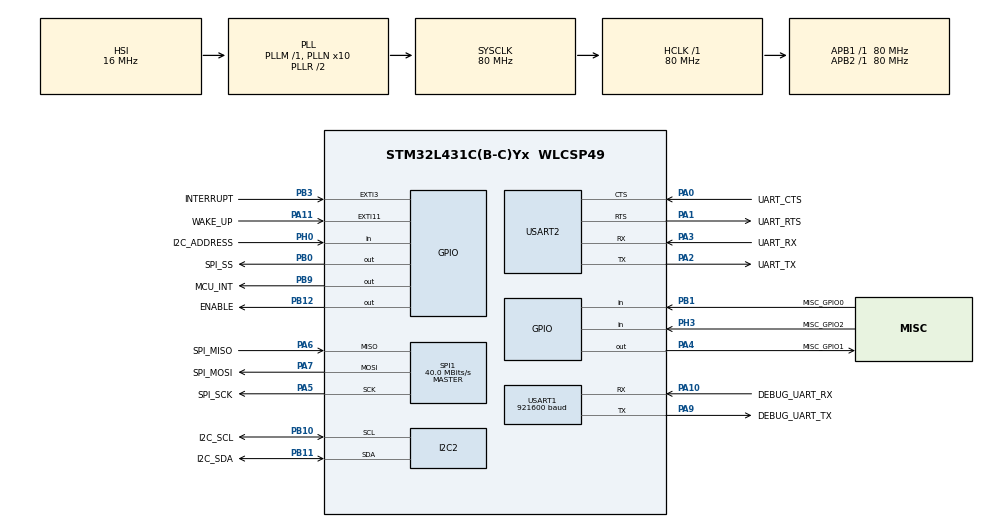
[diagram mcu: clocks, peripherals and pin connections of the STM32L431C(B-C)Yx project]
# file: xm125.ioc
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Dma.Request0=USART2_RX
Dma.Request1=USART2_TX
Dma.Request2=SPI1_RX
Dma.Request3=SPI1_TX
Dma.Request4=USART1_RX
Dma.SPI1_RX.2.Direction=DMA_PERIPH_TO_MEMORY
Dma.SPI1_RX.2.Instance=DMA1_Channel2
Dma.SPI1_RX.2.MemDataAlignment=DMA_MDATAALIGN_HALFWORD
Dma.SPI1_RX.2.MemInc=DMA_MINC_ENABLE
Dma.SPI1_RX.2.Mode=DMA_NORMAL
Dma.SPI1_RX.2.PeriphDataAlignment=DMA_PDATAALIGN_HALFWORD
Dma.SPI1_RX.2.PeriphInc=DMA_PINC_DISABLE
Dma.SPI1_RX.2.Priority=DMA_PRIORITY_LOW
Dma.SPI1_TX.3.Direction=DMA_MEMORY_TO_PERIPH
Dma.SPI1_TX.3.Instance=DMA1_Channel3
Dma.SPI1_TX.3.MemDataAlignment=DMA_MDATAALIGN_HALFWORD
Dma.SPI1_TX.3.MemInc=DMA_MINC_ENABLE
Dma.SPI1_TX.3.Mode=DMA_NORMAL
Dma.SPI1_TX.3.PeriphDataAlignment=DMA_PDATAALIGN_HALFWORD
Dma.SPI1_TX.3.PeriphInc=DMA_PINC_DISABLE
Dma.SPI1_TX.3.Priority=DMA_PRIORITY_LOW
Dma.USART1_RX.4.Direction=DMA_PERIPH_TO_MEMORY
Dma.USART1_RX.4.Instance=DMA1_Channel5
Dma.USART1_RX.4.MemDataAlignment=DMA_MDATAALIGN_BYTE
Dma.USART1_RX.4.MemInc=DMA_MINC_ENABLE
Dma.USART1_RX.4.Mode=DMA_NORMAL
Dma.USART1_RX.4.PeriphDataAlignment=DMA_PDATAALIGN_BYTE
Dma.USART1_RX.4.PeriphInc=DMA_PINC_DISABLE
Dma.USART1_RX.4.Priority=DMA_PRIORITY_LOW
Dma.USART2_RX.0.Direction=DMA_PERIPH_TO_MEMORY
Dma.USART2_RX.0.Instance=DMA1_Channel6
Dma.USART2_RX.0.MemDataAlignment=DMA_MDATAALIGN_BYTE
Dma.USART2_RX.0.MemInc=DMA_MINC_ENABLE
Dma.USART2_RX.0.Mode=DMA_NORMAL
Dma.USART2_RX.0.PeriphDataAlignment=DMA_PDATAALIGN_BYTE
Dma.USART2_RX.0.PeriphInc=DMA_PINC_DISABLE
Dma.USART2_RX.0.Priority=DMA_PRIORITY_LOW
Dma.USART2_TX.1.Direction=DMA_MEMORY_TO_PERIPH
Dma.USART2_TX.1.Instance=DMA1_Channel7
Dma.USART2_TX.1.MemDataAlignment=DMA_MDATAALIGN_BYTE
Dma.USART2_TX.1.MemInc=DMA_MINC_ENABLE
Dma.USART2_TX.1.Mode=DMA_NORMAL
Dma.USART2_TX.1.PeriphDataAlignment=DMA_PDATAALIGN_BYTE
Dma.USART2_TX.1.PeriphInc=DMA_PINC_DISABLE
Dma.USART2_TX.1.Priority=DMA_PRIORITY_LOW
I2C2.OwnAddress=0x52
I2C2.Timing=0x10D19CE4
Mcu.Family=STM32L4
Mcu.Name=STM32L431C(B-C)Yx
Mcu.Package=WLCSP49
NVIC.DMA1_Channel2_IRQn=true\:0\:0\:false\:false\:true\:false\:true\:true
NVIC.DMA1_Channel3_IRQn=true\:0\:0\:false\:false\:true\:false\:true\:true
NVIC.DMA1_Channel5_IRQn=true\:0\:0\:false\:false\:true\:false\:true\:true
NVIC.DMA1_Channel6_IRQn=true\:0\:0\:false\:false\:true\:false\:true\:true
NVIC.DMA1_Channel7_IRQn=true\:0\:0\:false\:false\:true\:false\:true\:true
NVIC.EXTI15_10_IRQn=true\:0\:0\:false\:false\:true\:true\:true\:true
NVIC.EXTI3_IRQn=true\:0\:0\:false\:false\:true\:true\:true\:true
NVIC.I2C2_EV_IRQn=true\:0\:0\:false\:false\:true\:true\:true\:true
NVIC.PriorityGroup=NVIC_PRIORITYGROUP_4
NVIC.RTC_Alarm_IRQn=true\:0\:0\:false\:false\:true\:true\:true\:true
NVIC.RTC_WKUP_IRQn=true\:0\:0\:false\:false\:true\:true\:true\:true
NVIC.USART2_IRQn=true\:0\:0\:false\:false\:true\:true\:true\:true
PA0.GPIO_Label=UART_CTS
PA0.Mode=CTS_RTS
PA0.Signal=USART2_CTS
PA1.GPIO_Label=UART_RTS
PA1.Mode=CTS_RTS
PA1.Signal=USART2_RTS
PA10.GPIO_Label=DEBUG_UART_RX
PA10.Mode=Asynchronous
PA10.Signal=USART1_RX
PA11.GPIO_Label=WAKE_UP
PA11.GPIO_ModeDefaultEXTI=GPIO_MODE_IT_RISING_FALLING
PA11.GPIO_PuPd=GPIO_PULLDOWN
PA11.Signal=GPXTI11
PA2.GPIO_Label=UART_TX
PA2.Mode=Asynchronous
PA2.Signal=USART2_TX
PA3.GPIO_Label=UART_RX
PA3.Mode=Asynchronous
PA3.Signal=USART2_RX
PA4.GPIO_Label=MISC_GPIO1
PA4.GPIO_PuPd=GPIO_PULLDOWN
PA4.GPIO_Speed=GPIO_SPEED_FREQ_VERY_HIGH
PA4.Signal=GPIO_Output
PA5.GPIO_Label=SPI_SCK
PA5.Mode=Full_Duplex_Master
PA5.Signal=SPI1_SCK
PA6.GPIO_Label=SPI_MISO
PA6.Mode=Full_Duplex_Master
PA6.Signal=SPI1_MISO
PA7.GPIO_Label=SPI_MOSI
PA7.Mode=Full_Duplex_Master
PA7.Signal=SPI1_MOSI
PA9.GPIO_Label=DEBUG_UART_TX
PA9.Mode=Asynchronous
PA9.Signal=USART1_TX
PB0.GPIO_Label=SPI_SS
PB0.GPIO_ModeDefaultOutputPP=GPIO_MODE_OUTPUT_PP
PB0.GPIO_Speed=GPIO_SPEED_FREQ_VERY_HIGH
PB0.Signal=GPIO_Output
PB1.GPIO_Label=MISC_GPIO0
PB1.GPIO_PuPd=GPIO_PULLDOWN
PB1.Signal=GPIO_Input
PB10.GPIO_Label=I2C_SCL
PB10.GPIO_Pu=GPIO_PULLUP
PB10.Mode=I2C
PB10.Signal=I2C2_SCL
PB11.GPIO_Label=I2C_SDA
PB11.GPIO_Pu=GPIO_PULLUP
PB11.Mode=I2C
PB11.Signal=I2C2_SDA
PB12.GPIO_Label=ENABLE
PB12.GPIO_Speed=GPIO_SPEED_FREQ_VERY_HIGH
PB12.PinState=GPIO_PIN_RESET
PB12.Signal=GPIO_Output
PB3\ (JTDO-TRACESWO).GPIO_Label=INTERRUPT
PB3\ (JTDO-TRACESWO).GPIO_PuPd=GPIO_PULLDOWN
PB3\ (JTDO-TRACESWO).Signal=GPXTI3
PB9.GPIO_Label=MCU_INT
PB9.GPIO_Speed=GPIO_SPEED_FREQ_VERY_HIGH
PB9.Signal=GPIO_Output
PH0-OSC_IN\ (PH0).GPIO_Label=I2C_ADDRESS
PH0-OSC_IN\ (PH0).GPIO_PuPd=GPIO_PULLDOWN
PH0-OSC_IN\ (PH0).Signal=GPIO_Input
PH3-BOOT0.GPIO_Label=MISC_GPIO2
PH3-BOOT0.GPIO_PuPd=GPIO_PULLDOWN
PH3-BOOT0.Signal=GPIO_Input
ProjectManager.HeapSize=0x200
ProjectManager.StackSize=0x1400
ProjectManager.TargetToolchain=STM32CubeIDE
RCC.ADCFreq_Value=64000000
RCC.AHBFreq_Value=80000000
RCC.APB1Freq_Value=80000000
RCC.APB1TimFreq_Value=80000000
RCC.APB2Freq_Value=80000000
RCC.APB2TimFreq_Value=80000000
RCC.CortexFreq_Value=80000000
RCC.HCLKFreq_Value=80000000
RCC.HSE_VALUE=8000000
RCC.HSI48_VALUE=48000000
RCC.HSI_VALUE=16000000
RCC.LSE_VALUE=32768
RCC.MSI_VALUE=4000000
RCC.PLLN=10
RCC.PLLSourceVirtual=RCC_PLLSOURCE_HSI
RCC.SYSCLKFreq_VALUE=80000000
RCC.SYSCLKSource=RCC_SYSCLKSOURCE_PLLCLK
RCC.VCOOutputFreq_Value=160000000
RTC.Alarm-Alarm\ A=RTC_ALARM_A
RTC.AsynchPrediv=31
RTC.Format=RTC_FORMAT_BIN
RTC.SynchPrediv=999
SPI1.BaudRatePrescaler=SPI_BAUDRATEPRESCALER_2
SPI1.CalculateBaudRate=40.0 MBits/s
SPI1.DataSize=SPI_DATASIZE_16BIT
SPI1.Direction=SPI_DIRECTION_2LINES
SPI1.Mode=SPI_MODE_MASTER
SPI1.VirtualType=VM_MASTER
USART1.BaudRate=921600
USART1.Parity=PARITY_EVEN
USART1.VirtualMode-Asynchronous=VM_ASYNC
USART1.WordLength=WORDLENGTH_9B
USART2.VirtualMode-Asynchronous=VM_ASYNC
VP_RTC_VS_RTC_Activate.Mode=RTC_Enabled
VP_RTC_VS_RTC_Alarm_A_Intern.Mode=Alarm A
VP_RTC_VS_RTC_Calendar.Mode=RTC_Calendar
VP_RTC_VS_RTC_WakeUp_intern.Mode=WakeUp
board=custom

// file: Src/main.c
/* USER CODE BEGIN Header */
/**
 ******************************************************************************
 * @file           : main.c
 * @brief          : Main program body
 ******************************************************************************
 * @attention
 *
 * <h2><center>&copy; Copyright (c) 2022 STMicroelectronics.
 * All rights reserved.</center></h2>
 *
 * This software component is licensed by ST under BSD 3-Clause license,
 * the "License"; You may not use this file except in compliance with the
 * License. You may obtain a copy of the License at:
 *                        opensource.org/licenses/BSD-3-Clause
 *
 ******************************************************************************
 */
/* USER CODE END Header */
#include "main.h"

/* USER CODE BEGIN Includes */

#include <inttypes.h>
#include <stdbool.h>
#include <stdio.h>

#include "acc_integration.h"

/* USER CODE END Includes */

/* USER CODE BEGIN PD */

extern int acconeer_main(int argc, char *argv[]);

/* USER CODE END PD */

I2C_HandleTypeDef hi2c2;

RTC_HandleTypeDef hrtc;

SPI_HandleTypeDef hspi1;
DMA_HandleTypeDef hdma_spi1_rx;
DMA_HandleTypeDef hdma_spi1_tx;

UART_HandleTypeDef huart1;
UART_HandleTypeDef huart2;
DMA_HandleTypeDef hdma_usart1_rx;
DMA_HandleTypeDef hdma_usart2_rx;
DMA_HandleTypeDef hdma_usart2_tx;

void SystemClock_Config(void);
static void MX_GPIO_Init(void);
static void MX_DMA_Init(void);
static void MX_USART2_UART_Init(void);
static void MX_SPI1_Init(void);
static void MX_I2C2_Init(void);
static void MX_USART1_UART_Init(void);
static void MX_RTC_Init(void);

int main(void)
{

  /* MCU Configuration--------------------------------------------------------*/

  /* Reset of all peripherals, Initializes the Flash interface and the Systick. */
  HAL_Init();

  /* Configure the system clock */
  SystemClock_Config();

  /* Initialize all configured peripherals */
  MX_GPIO_Init();
  MX_DMA_Init();
  MX_USART2_UART_Init();
  MX_SPI1_Init();
  MX_I2C2_Init();
  MX_USART1_UART_Init();
  MX_RTC_Init();
  /* USER CODE BEGIN 2 */

//  acconeer_main(0, NULL);
  acconeer_main_JJH_V2(0, NULL);

  /* USER CODE END 2 */

  /* Infinite loop */
	while (1)
	{

	}
}

void SystemClock_Config(void)
{
  RCC_OscInitTypeDef RCC_OscInitStruct = {0};
  RCC_ClkInitTypeDef RCC_ClkInitStruct = {0};

  /** Configure the main internal regulator output voltage
  */
  if (HAL_PWREx_ControlVoltageScaling(PWR_REGULATOR_VOLTAGE_SCALE1) != HAL_OK)
  {
    Error_Handler();
  }

  /** Initializes the RCC Oscillators according to the specified parameters
  * in the RCC_OscInitTypeDef structure.
  */
  RCC_OscInitStruct.OscillatorType = RCC_OSCILLATORTYPE_HSI|RCC_OSCILLATORTYPE_LSI;
  RCC_OscInitStruct.HSIState = RCC_HSI_ON;
  RCC_OscInitStruct.HSICalibrationValue = RCC_HSICALIBRATION_DEFAULT;
  RCC_OscInitStruct.LSIState = RCC_LSI_ON;
  RCC_OscInitStruct.PLL.PLLState = RCC_PLL_ON;
  RCC_OscInitStruct.PLL.PLLSource = RCC_PLLSOURCE_HSI;
  RCC_OscInitStruct.PLL.PLLM = 1;
  RCC_OscInitStruct.PLL.PLLN = 10;
  RCC_OscInitStruct.PLL.PLLP = RCC_PLLP_DIV7;
  RCC_OscInitStruct.PLL.PLLQ = RCC_PLLQ_DIV2;
  RCC_OscInitStruct.PLL.PLLR = RCC_PLLR_DIV2;
  if (HAL_RCC_OscConfig(&RCC_OscInitStruct) != HAL_OK)
  {
    Error_Handler();
  }

  /** Initializes the CPU, AHB and APB buses clocks
  */
  RCC_ClkInitStruct.ClockType = RCC_CLOCKTYPE_HCLK|RCC_CLOCKTYPE_SYSCLK
                              |RCC_CLOCKTYPE_PCLK1|RCC_CLOCKTYPE_PCLK2;
  RCC_ClkInitStruct.SYSCLKSource = RCC_SYSCLKSOURCE_PLLCLK;
  RCC_ClkInitStruct.AHBCLKDivider = RCC_SYSCLK_DIV1;
  RCC_ClkInitStruct.APB1CLKDivider = RCC_HCLK_DIV1;
  RCC_ClkInitStruct.APB2CLKDivider = RCC_HCLK_DIV1;

  if (HAL_RCC_ClockConfig(&RCC_ClkInitStruct, FLASH_LATENCY_4) != HAL_OK)
  {
    Error_Handler();
  }
}

static void MX_I2C2_Init(void)
{

  hi2c2.Instance = I2C2;
  hi2c2.Init.Timing = 0x10D19CE4;
  hi2c2.Init.OwnAddress1 = 164;
  hi2c2.Init.AddressingMode = I2C_ADDRESSINGMODE_7BIT;
  hi2c2.Init.DualAddressMode = I2C_DUALADDRESS_DISABLE;
  hi2c2.Init.OwnAddress2 = 0;
  hi2c2.Init.OwnAddress2Masks = I2C_OA2_NOMASK;
  hi2c2.Init.GeneralCallMode = I2C_GENERALCALL_DISABLE;
  hi2c2.Init.NoStretchMode = I2C_NOSTRETCH_DISABLE;
  if (HAL_I2C_Init(&hi2c2) != HAL_OK)
  {
    Error_Handler();
  }

  /** Configure Analogue filter
  */
  if (HAL_I2CEx_ConfigAnalogFilter(&hi2c2, I2C_ANALOGFILTER_ENABLE) != HAL_OK)
  {
    Error_Handler();
  }

  /** Configure Digital filter
  */
  if (HAL_I2CEx_ConfigDigitalFilter(&hi2c2, 0) != HAL_OK)
  {
    Error_Handler();
  }

}

static void MX_RTC_Init(void)
{

  RTC_TimeTypeDef sTime = {0};
  RTC_DateTypeDef sDate = {0};
  RTC_AlarmTypeDef sAlarm = {0};

  /** Initialize RTC Only
  */
  hrtc.Instance = RTC;
  hrtc.Init.HourFormat = RTC_HOURFORMAT_24;
  hrtc.Init.AsynchPrediv = 31;
  hrtc.Init.SynchPrediv = 999;
  hrtc.Init.OutPut = RTC_OUTPUT_DISABLE;
  hrtc.Init.OutPutRemap = RTC_OUTPUT_REMAP_NONE;
  hrtc.Init.OutPutPolarity = RTC_OUTPUT_POLARITY_HIGH;
  hrtc.Init.OutPutType = RTC_OUTPUT_TYPE_OPENDRAIN;
  if (HAL_RTC_Init(&hrtc) != HAL_OK)
  {
    Error_Handler();
  }

  /** Initialize RTC and set the Time and Date
  */
  sTime.Hours = 0;
  sTime.Minutes = 0;
  sTime.Seconds = 0;
  sTime.DayLightSaving = RTC_DAYLIGHTSAVING_NONE;
  sTime.StoreOperation = RTC_STOREOPERATION_RESET;
  if (HAL_RTC_SetTime(&hrtc, &sTime, RTC_FORMAT_BIN) != HAL_OK)
  {
    Error_Handler();
  }
  sDate.WeekDay = RTC_WEEKDAY_MONDAY;
  sDate.Month = RTC_MONTH_JANUARY;
  sDate.Date = 1;
  sDate.Year = 0;

  if (HAL_RTC_SetDate(&hrtc, &sDate, RTC_FORMAT_BIN) != HAL_OK)
  {
    Error_Handler();
  }

  /** Enable the Alarm A
  */
  sAlarm.AlarmTime.Hours = 0;
  sAlarm.AlarmTime.Minutes = 0;
  sAlarm.AlarmTime.Seconds = 0;
  sAlarm.AlarmTime.SubSeconds = 0;
  sAlarm.AlarmTime.DayLightSaving = RTC_DAYLIGHTSAVING_NONE;
  sAlarm.AlarmTime.StoreOperation = RTC_STOREOPERATION_RESET;
  sAlarm.AlarmMask = RTC_ALARMMASK_NONE;
  sAlarm.AlarmSubSecondMask = RTC_ALARMSUBSECONDMASK_ALL;
  sAlarm.AlarmDateWeekDaySel = RTC_ALARMDATEWEEKDAYSEL_DATE;
  sAlarm.AlarmDateWeekDay = 1;
  sAlarm.Alarm = RTC_ALARM_A;
  if (HAL_RTC_SetAlarm_IT(&hrtc, &sAlarm, RTC_FORMAT_BIN) != HAL_OK)
  {
    Error_Handler();
  }

}

static void MX_SPI1_Init(void)
{

  /* SPI1 parameter configuration*/
  hspi1.Instance = SPI1;
  hspi1.Init.Mode = SPI_MODE_MASTER;
  hspi1.Init.Direction = SPI_DIRECTION_2LINES;
  hspi1.Init.DataSize = SPI_DATASIZE_16BIT;
  hspi1.Init.CLKPolarity = SPI_POLARITY_LOW;
  hspi1.Init.CLKPhase = SPI_PHASE_1EDGE;
  hspi1.Init.NSS = SPI_NSS_SOFT;
  hspi1.Init.BaudRatePrescaler = SPI_BAUDRATEPRESCALER_2;
  hspi1.Init.FirstBit = SPI_FIRSTBIT_MSB;
  hspi1.Init.TIMode = SPI_TIMODE_DISABLE;
  hspi1.Init.CRCCalculation = SPI_CRCCALCULATION_DISABLE;
  hspi1.Init.CRCPolynomial = 7;
  hspi1.Init.CRCLength = SPI_CRC_LENGTH_DATASIZE;
  hspi1.Init.NSSPMode = SPI_NSS_PULSE_ENABLE;
  if (HAL_SPI_Init(&hspi1) != HAL_OK)
  {
    Error_Handler();
  }

}

static void MX_USART1_UART_Init(void)
{

  huart1.Instance = USART1;
  huart1.Init.BaudRate = 921600;
  huart1.Init.WordLength = UART_WORDLENGTH_9B;
  huart1.Init.StopBits = UART_STOPBITS_1;
  huart1.Init.Parity = UART_PARITY_EVEN;
  huart1.Init.Mode = UART_MODE_TX_RX;
  huart1.Init.HwFlowCtl = UART_HWCONTROL_NONE;
  huart1.Init.OverSampling = UART_OVERSAMPLING_16;
  huart1.Init.OneBitSampling = UART_ONE_BIT_SAMPLE_DISABLE;
  huart1.AdvancedInit.AdvFeatureInit = UART_ADVFEATURE_NO_INIT;
  if (HAL_UART_Init(&huart1) != HAL_OK)
  {
    Error_Handler();
  }

}

static void MX_USART2_UART_Init(void)
{

  huart2.Instance = USART2;
  huart2.Init.BaudRate = 115200;
  huart2.Init.WordLength = UART_WORDLENGTH_8B;
  huart2.Init.StopBits = UART_STOPBITS_1;
  huart2.Init.Parity = UART_PARITY_NONE;
  huart2.Init.Mode = UART_MODE_TX_RX;
  huart2.Init.HwFlowCtl = UART_HWCONTROL_RTS_CTS;
  huart2.Init.OverSampling = UART_OVERSAMPLING_16;
  huart2.Init.OneBitSampling = UART_ONE_BIT_SAMPLE_DISABLE;
  huart2.AdvancedInit.AdvFeatureInit = UART_ADVFEATURE_NO_INIT;
  if (HAL_UART_Init(&huart2) != HAL_OK)
  {
    Error_Handler();
  }

}

static void MX_DMA_Init(void)
{

  /* DMA controller clock enable */
  __HAL_RCC_DMA1_CLK_ENABLE();

  /* DMA interrupt init */
  /* DMA1_Channel2_IRQn interrupt configuration */
  HAL_NVIC_SetPriority(DMA1_Channel2_IRQn, 0, 0);
  HAL_NVIC_EnableIRQ(DMA1_Channel2_IRQn);
  /* DMA1_Channel3_IRQn interrupt configuration */
  HAL_NVIC_SetPriority(DMA1_Channel3_IRQn, 0, 0);
  HAL_NVIC_EnableIRQ(DMA1_Channel3_IRQn);
  /* DMA1_Channel5_IRQn interrupt configuration */
  HAL_NVIC_SetPriority(DMA1_Channel5_IRQn, 0, 0);
  HAL_NVIC_EnableIRQ(DMA1_Channel5_IRQn);
  /* DMA1_Channel6_IRQn interrupt configuration */
  HAL_NVIC_SetPriority(DMA1_Channel6_IRQn, 0, 0);
  HAL_NVIC_EnableIRQ(DMA1_Channel6_IRQn);
  /* DMA1_Channel7_IRQn interrupt configuration */
  HAL_NVIC_SetPriority(DMA1_Channel7_IRQn, 0, 0);
  HAL_NVIC_EnableIRQ(DMA1_Channel7_IRQn);

}

static void MX_GPIO_Init(void)
{
  GPIO_InitTypeDef GPIO_InitStruct = {0};

  /* GPIO Ports Clock Enable */
  __HAL_RCC_GPIOB_CLK_ENABLE();
  __HAL_RCC_GPIOH_CLK_ENABLE();
  __HAL_RCC_GPIOA_CLK_ENABLE();

  /*Configure GPIO pin Output Level */
  HAL_GPIO_WritePin(GPIOB, MCU_INT_Pin|ENABLE_Pin|SPI_SS_Pin, GPIO_PIN_RESET);

  /*Configure GPIO pin Output Level */
  HAL_GPIO_WritePin(MISC_GPIO1_GPIO_Port, MISC_GPIO1_Pin, GPIO_PIN_RESET);

  /*Configure GPIO pin : INTERRUPT_Pin */
  GPIO_InitStruct.Pin = INTERRUPT_Pin;
  GPIO_InitStruct.Mode = GPIO_MODE_IT_RISING;
  GPIO_InitStruct.Pull = GPIO_PULLDOWN;
  HAL_GPIO_Init(INTERRUPT_GPIO_Port, &GPIO_InitStruct);

  /*Configure GPIO pins : MISC_GPIO2_Pin I2C_ADDRESS_Pin */
  GPIO_InitStruct.Pin = MISC_GPIO2_Pin|I2C_ADDRESS_Pin;
  GPIO_InitStruct.Mode = GPIO_MODE_INPUT;
  GPIO_InitStruct.Pull = GPIO_PULLDOWN;
  HAL_GPIO_Init(GPIOH, &GPIO_InitStruct);

  /*Configure GPIO pin : WAKE_UP_Pin */
  GPIO_InitStruct.Pin = WAKE_UP_Pin;
  GPIO_InitStruct.Mode = GPIO_MODE_IT_RISING_FALLING;
  GPIO_InitStruct.Pull = GPIO_PULLDOWN;
  HAL_GPIO_Init(WAKE_UP_GPIO_Port, &GPIO_InitStruct);

  /*Configure GPIO pins : MCU_INT_Pin ENABLE_Pin SPI_SS_Pin */
  GPIO_InitStruct.Pin = MCU_INT_Pin|ENABLE_Pin|SPI_SS_Pin;
  GPIO_InitStruct.Mode = GPIO_MODE_OUTPUT_PP;
  GPIO_InitStruct.Pull = GPIO_NOPULL;
  GPIO_InitStruct.Speed = GPIO_SPEED_FREQ_VERY_HIGH;
  HAL_GPIO_Init(GPIOB, &GPIO_InitStruct);

  /*Configure GPIO pin : MISC_GPIO0_Pin */
  GPIO_InitStruct.Pin = MISC_GPIO0_Pin;
  GPIO_InitStruct.Mode = GPIO_MODE_INPUT;
  GPIO_InitStruct.Pull = GPIO_PULLDOWN;
  HAL_GPIO_Init(MISC_GPIO0_GPIO_Port, &GPIO_InitStruct);

  /*Configure GPIO pin : MISC_GPIO1_Pin */
  GPIO_InitStruct.Pin = MISC_GPIO1_Pin;
  GPIO_InitStruct.Mode = GPIO_MODE_OUTPUT_PP;
  GPIO_InitStruct.Pull = GPIO_PULLDOWN;
  GPIO_InitStruct.Speed = GPIO_SPEED_FREQ_VERY_HIGH;
  HAL_GPIO_Init(MISC_GPIO1_GPIO_Port, &GPIO_InitStruct);

  /* EXTI interrupt init*/
  HAL_NVIC_SetPriority(EXTI3_IRQn, 0, 0);
  HAL_NVIC_EnableIRQ(EXTI3_IRQn);

  HAL_NVIC_SetPriority(EXTI15_10_IRQn, 0, 0);
  HAL_NVIC_EnableIRQ(EXTI15_10_IRQn);

}

void Error_Handler(void)
{
  /* USER CODE BEGIN Error_Handler_Debug */
	/* User can add his own implementation to report the HAL error return state */
	NVIC_SystemReset();
  /* USER CODE END Error_Handler_Debug */
}
